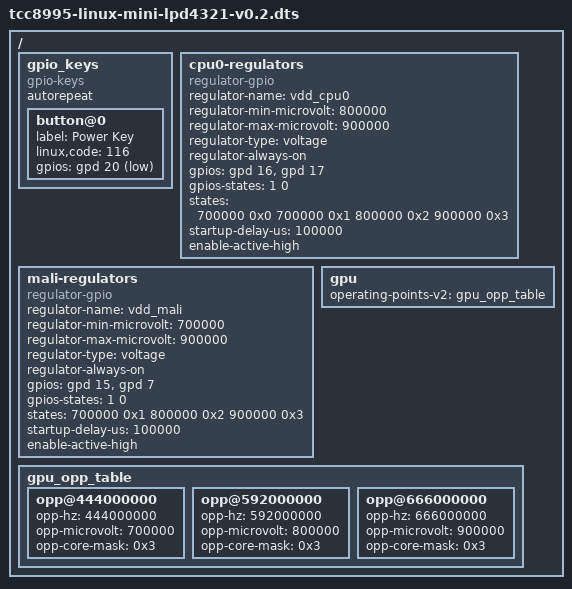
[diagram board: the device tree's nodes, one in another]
// SPDX-License-Identifier: (GPL-2.0-or-later OR MIT)
/*
 * Copyright (C) Telechips Inc.
 */

/dts-v1/;

#include "tcc8995-linux-mini.dtsi"

/ {
	/* Describe here after remove this statement if you have something to be override. */
	gpio_keys {
		compatible = "gpio-keys";
		#address-cells = <1>;
		#size-cells = <0>;
		autorepeat;
		button@0 {
			label = "Power Key";
			linux,code = <116>;
			gpios = <&gpd 20 1>;
		};
	};

	cpu0-regulators {
		compatible = "regulator-gpio";

		regulator-name = "vdd_cpu0";
		regulator-min-microvolt = <800000>;
		regulator-max-microvolt = <900000>;
		regulator-type = "voltage";
		regulator-always-on;

		gpios = <&gpd 16 0x4
			&gpd 17 0x4>;
		gpios-states = <1 0>;

		states = < 700000 0x0
			700000 0x1
			800000 0x2
			900000 0x3
			>;

		startup-delay-us = <100000>;
		enable-active-high;
	};

	mali-regulators {
	        compatible = "regulator-gpio";

	        regulator-name = "vdd_mali";
	        regulator-min-microvolt = <700000>;
	        regulator-max-microvolt = <900000>;
	        regulator-type = "voltage";
	        regulator-always-on;

	        gpios = <&gpd 15 0x4
	                &gpd 7 0x4>;
	        gpios-states = <1 0>;

	        states = < 700000 0x1
	                800000 0x2
	                900000 0x3
	                >;

	        startup-delay-us = <100000>;
	        enable-active-high;
	};

	gpu {
	        operating-points-v2 = <&gpu_opp_table>;
	};

	gpu_opp_table {
	    opp@444000000 {
		opp-hz = /bits/ 64 <444000000>;
		opp-microvolt = <700000>;
		opp-core-mask = /bits/ 64 <0x3>;
	    };
	    opp@592000000 {
	        opp-hz = /bits/ 64 <592000000>;
	        opp-microvolt = <800000>;
	        opp-core-mask = /bits/ 64 <0x3>;
	    };
	    opp@666000000 {
	        opp-hz = /bits/ 64 <666000000>;
	        opp-microvolt = <900000>;
	        opp-core-mask = /bits/ 64 <0x3>;
	    };
	};
};
